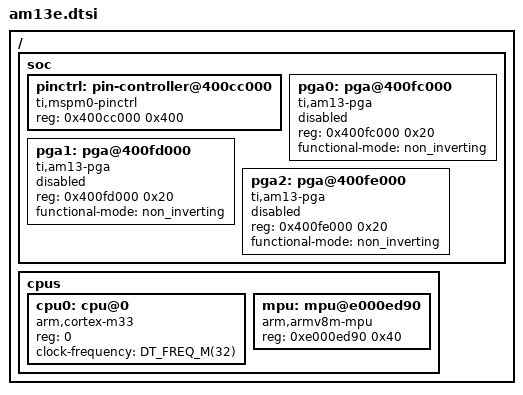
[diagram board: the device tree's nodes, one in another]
/*
 * Copyright (c) 2026 Texas Instruments Incorporated
 *
 * SPDX-License-Identifier: Apache-2.0
 */

#include <arm/armv8-m.dtsi>
#include <mem.h>
#include <freq.h>

/ {
	soc {
		pinctrl: pin-controller@400cc000 {
			compatible = "ti,mspm0-pinctrl";
			reg = <0x400cc000 0x400>;
		};

		pga0: pga@400fc000 {
			compatible = "ti,am13-pga";
			reg = <0x400fc000 0x20>;
			functional-mode = "non_inverting";
			status = "disabled";
		};

		pga1: pga@400fd000 {
			compatible = "ti,am13-pga";
			reg = <0x400fd000 0x20>;
			functional-mode = "non_inverting";
			status = "disabled";
		};

		pga2: pga@400fe000 {
			compatible = "ti,am13-pga";
			reg = <0x400fe000 0x20>;
			functional-mode = "non_inverting";
			status = "disabled";
		};
	};

	cpus {
		#address-cells = <1>;
		#size-cells = <0>;

		cpu0: cpu@0 {
			compatible = "arm,cortex-m33";
			reg = <0>;
			device_type = "cpu";
			#address-cells = <1>;
			#size-cells = <1>;
			clock-frequency = <DT_FREQ_M(32)>;
		};

		mpu: mpu@e000ed90 {
			compatible = "arm,armv8m-mpu";
			reg = <0xe000ed90 0x40>;
		};
	};
};
